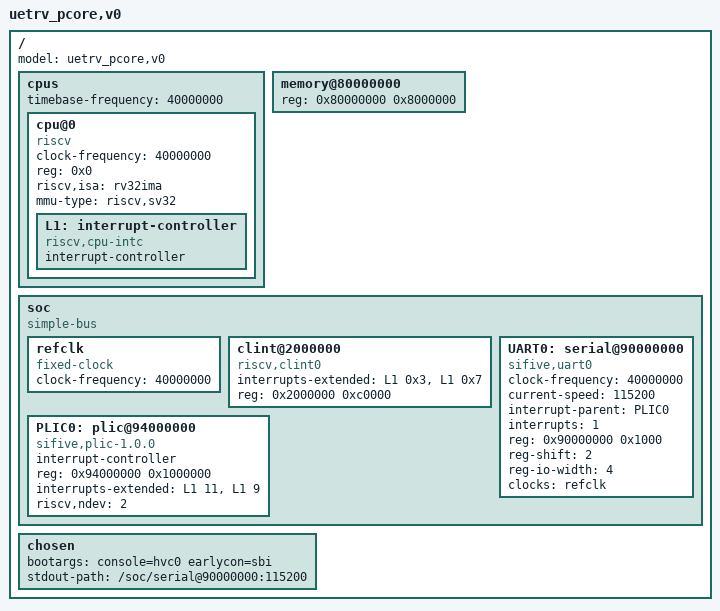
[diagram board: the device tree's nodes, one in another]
/dts-v1/;

/ {
	#address-cells = <0x1>;
	#size-cells = <0x1>;
	model = "uetrv_pcore,v0";
//	compatible = "uetrv_pcore,v0";
	cpus {
		#address-cells = <0x1>;
		#size-cells = <0x0>;
		timebase-frequency = <40000000>;
		cpu@0 {
			clock-frequency = <40000000>;
			device_type = "cpu";
			reg = <0x0>;
		//	status = "okay";
			compatible = "riscv";
			riscv,isa = "rv32ima";
			mmu-type = "riscv,sv32";
                //        tlb-split;
			L1: interrupt-controller {
                             //   #address-cells = <1>;
				#interrupt-cells = <1>;
				interrupt-controller;
				compatible = "riscv,cpu-intc";
			};
		};
	};
	memory@80000000 {
		device_type = "memory";
		reg = <0x80000000 0x8000000>;
	};
	soc {
		#address-cells = <0x1>;
		#size-cells = <0x1>;
		compatible = "simple-bus";
		ranges;

                refclk: refclk {
			#clock-cells = <0>;
			compatible = "fixed-clock";
			clock-frequency = <40000000>;
	//		clock-output-names = "xtal";
		}; 


		clint@2000000 {
			compatible = "riscv,clint0";
			interrupts-extended = <&L1 0x3 &L1 0x7>;
			reg = <0x2000000 0xc0000>;
		};

		PLIC0: plic@94000000 {
			#interrupt-cells = <0x1>;
			interrupt-controller;
			compatible = "sifive,plic-1.0.0"; // , "riscv,plic0"
			reg = <0x94000000 0x1000000>;
			interrupts-extended = <&L1 11 &L1 9>; 
			riscv,ndev = <2>;
		}; 
                
                UART0: serial@90000000 {
      			compatible = "sifive,uart0";
      			clock-frequency = <40000000>;
      			current-speed = <115200>;
      		        interrupt-parent = <&PLIC0>;
                        interrupts = <1>;
                        reg = <0x90000000 0x1000>;
      			reg-shift = <2>;    // regs are spaced on 32 bit boundary
      			reg-io-width = <4>; // only 32-bit access are supported
                        clocks = <&refclk>;
    		}; 
		
	}; 
	
      
    	chosen {
               bootargs = "console=hvc0 earlycon=sbi"; 
               stdout-path = "/soc/serial@90000000:115200"; 
    	};
};
